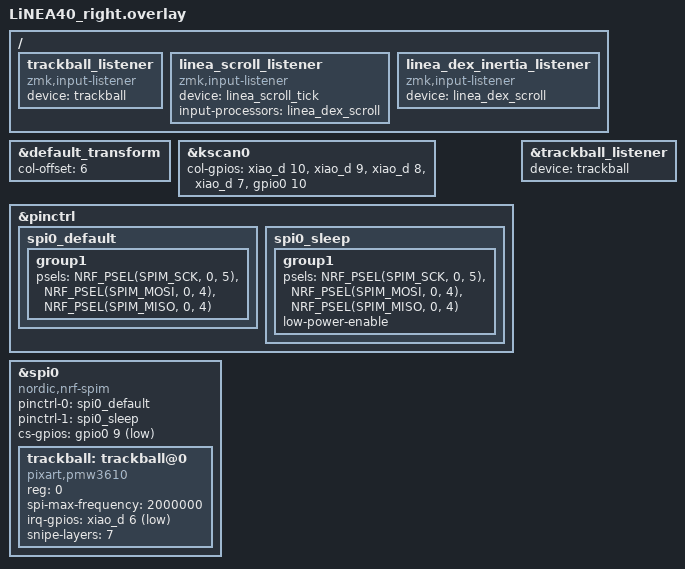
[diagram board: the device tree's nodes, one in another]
#include "LiNEA40.dtsi"
&default_transform {
    col-offset = <6>;
};

&kscan0 {
    col-gpios
        = <&xiao_d 10 GPIO_ACTIVE_HIGH> //col0-D10
        , <&xiao_d 9 GPIO_ACTIVE_HIGH>  //col1-D9
        , <&xiao_d 8 GPIO_ACTIVE_HIGH>  //col2-D8
        , <&xiao_d 7 GPIO_ACTIVE_HIGH>  //col3-D7
        , <&gpio0 10 GPIO_ACTIVE_HIGH>  //col4-NFC2
        ;
};

/ {
    trackball_listener {
        compatible = "zmk,input-listener";
        device = <&trackball>;

    };

    // スクロールのすき間を埋める処理（linea_scroll_tick）が送り出す信号を、そのまま Mac に送る
    linea_scroll_listener {
        compatible = "zmk,input-listener";
        device = <&linea_scroll_tick>;
        input-processors = <&linea_dex_scroll>;
    };

    // DeX モードのスクロールの慣性（linea_dex_scroll）が流す段を、そのまま送る（向き・倍率はもうかけてある）
    linea_dex_inertia_listener {
        compatible = "zmk,input-listener";
        device = <&linea_dex_scroll>;
    };
};


&pinctrl {
    spi0_default: spi0_default {
        group1 {
            psels = <NRF_PSEL(SPIM_SCK, 0, 5)>   // SCLK-D5
                  , <NRF_PSEL(SPIM_MOSI, 0, 4)>  // SDIO-D4
                  , <NRF_PSEL(SPIM_MISO, 0, 4)>  // SDIO-D4
                  ;
        };
    };

    spi0_sleep: spi0_sleep {
        group1 {
            psels = <NRF_PSEL(SPIM_SCK, 0, 5)>   // SCLK-D5
                  , <NRF_PSEL(SPIM_MOSI, 0, 4)>  // SDIO-D4
                  , <NRF_PSEL(SPIM_MISO, 0, 4)>  // SDIO-D4
                  ;
            low-power-enable;
        };
    };
};

&spi0 {
    status = "okay";
    compatible = "nordic,nrf-spim";
    pinctrl-0 = <&spi0_default>;
    pinctrl-1 = <&spi0_sleep>;
    pinctrl-names = "default", "sleep";
    cs-gpios = <&gpio0 9 GPIO_ACTIVE_LOW>; //NCS-NFC1

    trackball: trackball@0 {
        status = "okay";
        compatible = "pixart,pmw3610";
        reg = <0>;
        spi-max-frequency = <2000000>;
        irq-gpios = <&xiao_d 6 (GPIO_ACTIVE_LOW | GPIO_PULL_UP)>; //MOT-D6
        // automouse-layer は使わない（LiNEA40.keymap の linea_aml でオートマウスを動かす）
        snipe-layers = <7>;
        // scroll-layers は使わない（LiNEA40.keymap の scroller で、加速つきのスクロールにする）
        //scroll-layers = <4 5 6>;
    };
};

&trackball_listener {
    status = "okay";
    device = <&trackball>;
};
